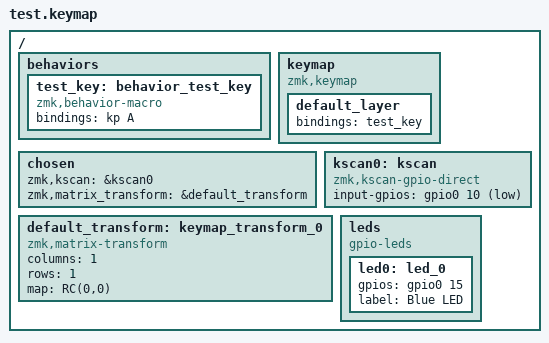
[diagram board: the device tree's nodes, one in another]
/*
 * Minimal test firmware for Nice!nano v2
 * 1. Blinks onboard LED (P0.15)
 * 2. Sends "A" when P0.10 is shorted to GND
 */

#include <behaviors.dtsi>
#include <dt-bindings/zmk/keys.h>

/ {
    behaviors {
        test_key: behavior_test_key {
            compatible = "zmk,behavior-macro";
            #binding-cells = <0>;
            bindings = <&kp A>;
        };
    };

    keymap {
        compatible = "zmk,keymap";

        default_layer {
            bindings = <
                &test_key
            >;
        };
    };

    chosen {
        zmk,kscan = &kscan0;
        zmk,matrix_transform = &default_transform;
    };

    kscan0: kscan {
        compatible = "zmk,kscan-gpio-direct";
        input-gpios = <&gpio0 10 (GPIO_ACTIVE_LOW | GPIO_PULL_UP)>;
    };

    default_transform: keymap_transform_0 {
        compatible = "zmk,matrix-transform";
        columns = <1>;
        rows = <1>;
        map = <RC(0,0)>;
    };

    leds {
        compatible = "gpio-leds";
        led0: led_0 {
            gpios = <&gpio0 15 GPIO_ACTIVE_HIGH>;
            label = "Blue LED";
        };
    };
};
